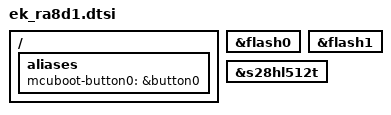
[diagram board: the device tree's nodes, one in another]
/* Delete Zephyr-default partitions before redefining them. */
&flash0 { /delete-node/ partitions; };
&flash1 { /delete-node/ partitions; };
&s28hl512t { /delete-node/ partitions; };

/ {
	aliases {
		mcuboot-button0 = &button0;
	};
};

#include "generated/ek_ra8d1.dtsi"
